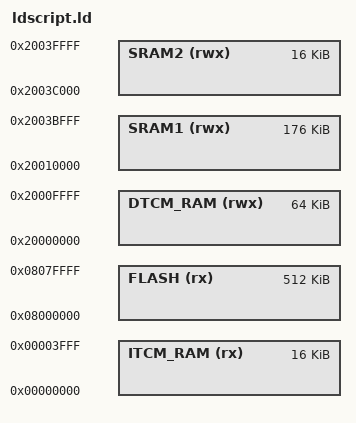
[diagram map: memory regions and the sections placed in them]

/* Linker script for STM32F722RE Device with 512KByte FLASH, 256KByte RAM */

/* Specify the memory areas */
MEMORY
{
  ITCM_RAM (rx)   : ORIGIN = 0x00000000, LENGTH = 16K

  DTCM_RAM (rwx)  : ORIGIN = 0x20000000, LENGTH = 64K
  SRAM1 (rwx)     : ORIGIN = 0x20010000, LENGTH = 176K
  SRAM2 (rwx)     : ORIGIN = 0x2003C000, LENGTH = 16K

  FLASH (rx)      : ORIGIN = 0x08000000, LENGTH = 512K
}

REGION_ALIAS("RAM_CODE", ITCM_RAM)
REGION_ALIAS("RAM_DATA", DTCM_RAM)
REGION_ALIAS("DMA_DATA", SRAM1)

INCLUDE "variants/ldscript_gen.ld"
